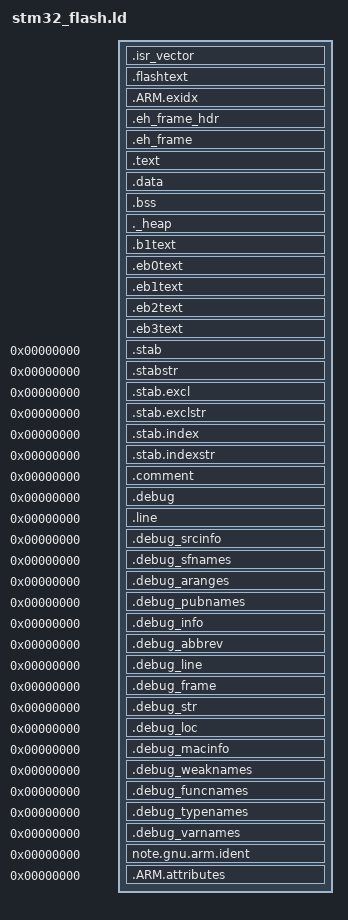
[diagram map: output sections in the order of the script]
/*
Common part of the linker scripts for STR71x devices in FLASH mode
(that is, the FLASH is seen at 0)
Copyright RAISONANCE 2005
You can use, modify and distribute thisfile freely, but without any waranty.
*/

ENTRY(exceptions_vectors)

/* Sections Definitions */

SECTIONS
{
    /* for Cortex devices, the beginning of the startup code is stored in the .isr_vector section, which goes to FLASH */
    .isr_vector :
    {
	. = ALIGN(4);
        KEEP(*(.isr_vector))            /* Startup code */
	. = ALIGN(4);
    } >FLASH
 
    /* for some STRx devices, the beginning of the startup code is stored in the .flashtext section, which goes to FLASH */
    .flashtext :
    {
	. = ALIGN(4);
        *(.flashtext)            /* Startup code */
	. = ALIGN(4);
    } >FLASH
 
     /* .ARM.exidx is sorted, so has to go in its own output section.  */
	__exidx_start = .;
	.ARM.exidx :
	{
		*(.ARM.exidx* .gnu.linkonce.armexidx.*)
	} >FLASH
    __exidx_end = .;
	
 	.eh_frame_hdr : ALIGN (4)
	{
		KEEP (*(.eh_frame_hdr))
	} >FLASH
	.eh_frame : ALIGN (4)
	{
		KEEP (*(.eh_frame))
	} >FLASH
	
    /* the program code is stored in the .text section, which goes to Flash */
    .text :
    {
	    . = ALIGN(4);
        *(.text)                   /* remaining code */
        *(.text.*)                   /* remaining code */
	    . = ALIGN(4);
        *(.rodata)                 /* read-only data (constants) */
        *(.rodata*)
	    . = ALIGN(4);
        *(.glue_7)
        *(.glue_7t)
	    . = ALIGN(4);
        *(.gnu.linkonce.t.*)
        *(.gnu.linkonce.r.*)
	    . = ALIGN(4);
        *(.ARM.extab* .gnu.linkonce.armextab.*)
	    . = ALIGN(4);
        *(.gcc_except_table)
	    . = ALIGN(4);
        *(.vfp11_veneer)
       	.  = ALIGN(4);
        PROVIDE(__ctors_start__ = .);
	    KEEP(*(SORT(.ctors.*)))
	    KEEP(*(.ctors))
	    PROVIDE(__ctors_end__ = .);
	    .  = ALIGN(4);
	    PROVIDE(__dtors_start__ = .); 
	    KEEP(*(SORT(.dtors.*)))
	    KEEP(*(.dtors))
	    PROVIDE(__dtors_end__ = .);
	    . = ALIGN(4);
		KEEP(*(.init));
		. = ALIGN(4);
		__preinit_array_start = .;
		KEEP(*(.preinit_array));
		. = ALIGN(4);
		__preinit_array_end = .;
		__init_array_start = .;
		KEEP(*(SORT(.init_array.*)));
		. = ALIGN(4);
		KEEP(*(.init_array));
		. = ALIGN(4);
		__init_array_end = .;
		KEEP(*(.fini));
		. = ALIGN(4);
		__fini_array_start = .;
		KEEP(*(.fini_array));
		. = ALIGN(4);
		KEEP(*(SORT(.fini_array.*)));
		. = ALIGN(4);
		__fini_array_end = .;
   	 _etext = .;
	    /* This is used by the startup in order to initialize the .data secion */
   	 _sidata = _etext;
    } >FLASH
    
 	
    /* This is the initialized data section
    The program executes knowing that the data is in the RAM
    but the loader puts the initial values in the FLASH (inidata).
    It is one task of the startup to copy the initial values from FLASH to RAM. */
    .data  : AT ( _sidata )
    {
	    . = ALIGN(4);
        /* This is used by the startup in order to initialize the .data secion */
        _sdata = . ;
        
        *(.data)
        *(.data.*)
		*(.gnu.linkonce.d.*)
	    . = ALIGN(4);
	    /* This is used by the startup in order to initialize the .data secion */
   	 _edata = . ;
    } >RAM
    
    

    /* This is the uninitialized data section */
    .bss :
    {
	    . = ALIGN(4);
        /* This is used by the startup in order to initialize the .bss secion */
        _sbss = .;
        
        *(.bss)
        *(.bss.*)
        *(.gnu.linkonce.b.*)
        *(COMMON)
        
	    . = ALIGN(4);
	    /* This is used by the startup in order to initialize the .bss secion */
   	 _ebss = . ;
    } >RAM
    
    PROVIDE ( end = _ebss );
    PROVIDE ( _end = _ebss );
    
    /* This is the user stack section 
    This is just to check that there is enough RAM left for the User mode stack
    It should generate an error if it's full.
     */
    /*
    ._usrstack :
    {
	    . = ALIGN(4);
        _susrstack = . ;
        
        . = . + _Minimum_Stack_Size ;
        
	    . = ALIGN(4);
        _eusrstack = . ;
    } >RAM
    */
    ._heap :
    {
        . = ALIGN(4);
        _heap_start = .;
        . = . + 4;
    } > RAM
    
    PROVIDE( __heap_start = _heap_start );
    PROVIDE( __heap_end = _estack - _sys_stack_size );
   
    /* this is the FLASH Bank1 */
    /* the C or assembly source must explicitly place the code or data there
    using the "section" attribute */
    .b1text :
    {
        *(.b1text)                   /* remaining code */
        *(.b1rodata)                 /* read-only data (constants) */
        *(.b1rodata*)
    } >FLASHB1
    
    /* this is the EXTMEM */
    /* the C or assembly source must explicitly place the code or data there
    using the "section" attribute */
    
    /* EXTMEM Bank0 */
    .eb0text :
    {
        *(.eb0text)                   /* remaining code */
        *(.eb0rodata)                 /* read-only data (constants) */
        *(.eb0rodata*)
    } >EXTMEMB0
    
    /* EXTMEM Bank1 */
    .eb1text :
    {
        *(.eb1text)                   /* remaining code */
        *(.eb1rodata)                 /* read-only data (constants) */
        *(.eb1rodata*)
    } >EXTMEMB1
    
    /* EXTMEM Bank2 */
    .eb2text :
    {
        *(.eb2text)                   /* remaining code */
        *(.eb2rodata)                 /* read-only data (constants) */
        *(.eb2rodata*)
    } >EXTMEMB2
    
    /* EXTMEM Bank0 */
    .eb3text :
    {
        *(.eb3text)                   /* remaining code */
        *(.eb3rodata)                 /* read-only data (constants) */
        *(.eb3rodata*)
    } >EXTMEMB3
    
    
    /* after that it's only debugging information. */
    
    /* remove the debugging information from the standard libraries */
    /DISCARD/ :
    {
		libc.a ( * )
		libm.a ( * )
		libgcc.a ( * )
	}

    /* Stabs debugging sections.  */
    .stab          0 : { *(.stab) }
    .stabstr       0 : { *(.stabstr) }
    .stab.excl     0 : { *(.stab.excl) }
    .stab.exclstr  0 : { *(.stab.exclstr) }
    .stab.index    0 : { *(.stab.index) }
    .stab.indexstr 0 : { *(.stab.indexstr) }
    .comment       0 : { *(.comment) }
    /* DWARF debug sections.
       Symbols in the DWARF debugging sections are relative to the beginning
       of the section so we begin them at 0.  */
    /* DWARF 1 */
    .debug          0 : { *(.debug) }
    .line           0 : { *(.line) }
    /* GNU DWARF 1 extensions */
    .debug_srcinfo  0 : { *(.debug_srcinfo) }
    .debug_sfnames  0 : { *(.debug_sfnames) }
    /* DWARF 1.1 and DWARF 2 */
    .debug_aranges  0 : { *(.debug_aranges) }
    .debug_pubnames 0 : { *(.debug_pubnames) }
    /* DWARF 2 */
    .debug_info     0 : { *(.debug_info .gnu.linkonce.wi.*) }
    .debug_abbrev   0 : { *(.debug_abbrev) }
    .debug_line     0 : { *(.debug_line) }
    .debug_frame    0 : { *(.debug_frame) }
    .debug_str      0 : { *(.debug_str) }
    .debug_loc      0 : { *(.debug_loc) }
    .debug_macinfo  0 : { *(.debug_macinfo) }
    /* SGI/MIPS DWARF 2 extensions */
    .debug_weaknames 0 : { *(.debug_weaknames) }
    .debug_funcnames 0 : { *(.debug_funcnames) }
    .debug_typenames 0 : { *(.debug_typenames) }
    .debug_varnames  0 : { *(.debug_varnames) }
    
    note.gnu.arm.ident 0 : { KEEP (*(.note.gnu.arm.ident)) }
	.ARM.attributes 0 : { KEEP (*(.ARM.attributes)) }
	/DISCARD/ : { *(.note.GNU-stack) }
}


